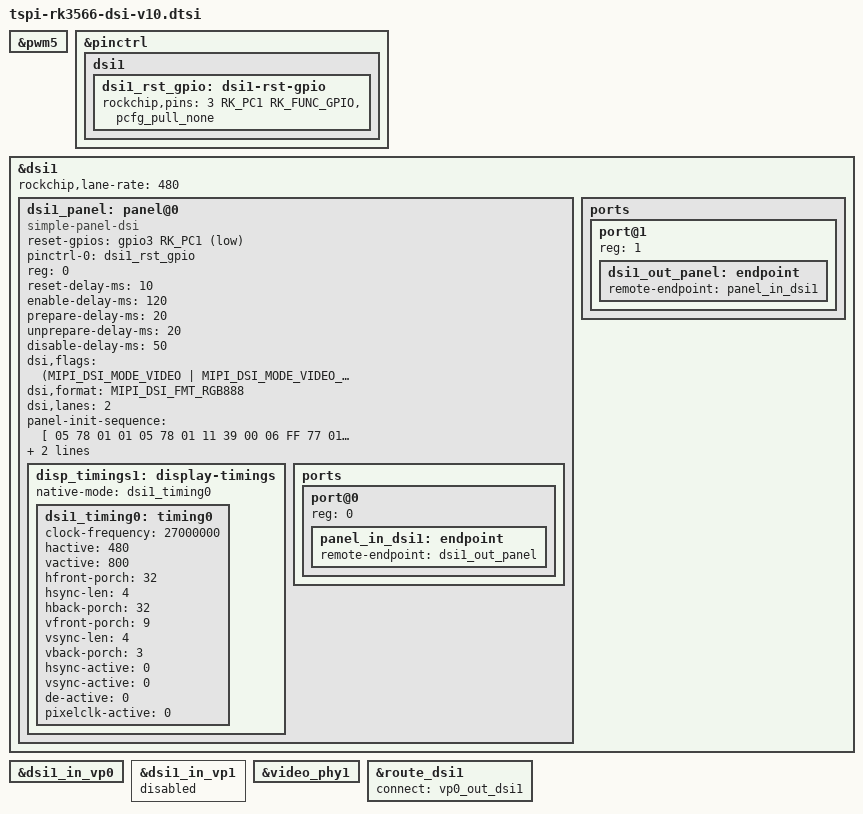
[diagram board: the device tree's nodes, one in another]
/*********************************************************************
 *           立创开发板不靠卖板赚钱，以培养中国工程师为己任  
 *         泰山派软硬件资料与相关扩展板软硬件资料官网全部开源
 *                      开发板官网：www.lckfb.com            
 *                     立创论坛：oshwhub.com/forum           
 *            关注B站：【立创开发板】，掌握我们的最新动态！  
 *********************************************************************
 * 文件名：tspi-rk3566-dsi-v10.dtsi
 * 描述：mipi 屏幕
 * 更新:
 * 时间          作者           联系           说明
 * 2023-09-13   吴才成    1378913492@qq.com   v1.0.0
 *********************************************************************/
/ {
	/*backlight: backlight {
		compatible = "pwm-backlight";
		pwms = <&pwm5 0 25000 0>;
		brightness-levels = <
			  0  20  20  21  21  22  22  23
			 23  24  24  25  25  26  26  27
			 27  28  28  29  29  30  30  31
			 31  32  32  33  33  34  34  35
			 35  36  36  37  37  38  38  39
			 40  41  42  43  44  45  46  47
			 48  49  50  51  52  53  54  55
			 56  57  58  59  60  61  62  63
			 64  65  66  67  68  69  70  71
			 72  73  74  75  76  77  78  79
			 80  81  82  83  84  85  86  87
			 88  89  90  91  92  93  94  95
			 96  97  98  99 100 101 102 103
			104 105 106 107 108 109 110 111
			112 113 114 115 116 117 118 119
			120 121 122 123 124 125 126 127
			128 129 130 131 132 133 134 135
			136 137 138 139 140 141 142 143
			144 145 146 147 148 149 150 151
			152 153 154 155 156 157 158 159
			160 161 162 163 164 165 166 167
			168 169 170 171 172 173 174 175
			176 177 178 179 180 181 182 183
			184 185 186 187 188 189 190 191
			192 193 194 195 196 197 198 199
			200 201 202 203 204 205 206 207
			208 209 210 211 212 213 214 215
			216 217 218 219 220 221 222 223
			224 225 226 227 228 229 230 231
			232 233 234 235 236 237 238 239
			240 241 242 243 244 245 246 247
			248 249 250 251 252 253 254 255
		>;
		default-brightness-level = <255>;
	};*/
};

&pwm5 {
	status = "okay";
};


&pinctrl {
	dsi1 {
		dsi1_rst_gpio: dsi1-rst-gpio {
			rockchip,pins = <3 RK_PC1 RK_FUNC_GPIO &pcfg_pull_none>;
		};
	};
};

/*
 * video_phy1 needs to be enabled
 * when dsi1 is enabled
 */
&dsi1 {
	status = "okay";
};

&dsi1_in_vp0 {
	status = "okay";
};

&dsi1_in_vp1 {
	status = "disabled";
};

&video_phy1 {
	status = "okay";
};

&route_dsi1 {
	status = "okay";//wucaicheng mipi okay
	connect = <&vp0_out_dsi1>;
};

//默认 8寸800x1280
&dsi1 {
	status = "okay";
	rockchip,lane-rate = <480>;
	dsi1_panel: panel@0 {
		status = "okay";
		compatible = "simple-panel-dsi";
		reset-gpios = <&gpio3 RK_PC1 GPIO_ACTIVE_LOW>;
		pinctrl-names = "default";
		pinctrl-0 = <&dsi1_rst_gpio>;
		reg = <0>;
		/*backlight = <&backlight>;*/
		reset-delay-ms = <10>;
		enable-delay-ms = <120>;
		prepare-delay-ms = <20>;
		unprepare-delay-ms = <20>;
		disable-delay-ms = <50>;
		dsi,flags = <(MIPI_DSI_MODE_VIDEO | MIPI_DSI_MODE_VIDEO_BURST |
			MIPI_DSI_MODE_LPM | MIPI_DSI_MODE_EOT_PACKET)>;
		dsi,format = <MIPI_DSI_FMT_RGB888>;
		dsi,lanes  = <2>;
		panel-init-sequence = [
			// init code
			05 78 01 01
			05 78 01 11
			39 00 06 FF 77 01 00 00 11
			15 00 02 D1 11
			15 00 02 55 B0 // 80 90 b0
			39 00 06 FF 77 01 00 00 10
			39 00 03 C0 63 00
			39 00 03 C1 09 02
			39 00 03 C2 37 08
			15 00 02 C7 00 // x-dir rotate 0:0x00,rotate 180:0x04
			15 00 02 CC 38
			39 00 11 B0 00 11 19 0C 10 06 07 0A 09 22 04 10 0E 28 30 1C
			39 00 11 B1 00 12 19 0D 10 04 06 07 08 23 04 12 11 28 30 1C
			39 00 06 FF 77 01 00 00 11 // enable  bk fun of  command 2  BK1
			15 00 02 B0 4D
			15 00 02 B1 60 // 0x56  0x4a  0x5b
			15 00 02 B2 07
			15 00 02 B3 80
			15 00 02 B5 47
			15 00 02 B7 8A
			15 00 02 B8 21
			15 00 02 C1 78
			15 00 02 C2 78
			15 64 02 D0 88
			39 00 04 E0 00 00 02
			39 00 0C E1 01 A0 03 A0 02 A0 04 A0 00 44 44
			39 00 0D E2 00 00 00 00 00 00 00 00 00 00 00 00
			39 00 05 E3 00 00 33 33
			39 00 03 E4 44 44
			39 00 11 E5 01 26 A0 A0 03 28 A0 A0 05 2A A0 A0 07 2C A0 A0
			39 00 05 E6 00 00 33 33
			39 00 03 E7 44 44
			39 00 11 E8 02 26 A0 A0 04 28 A0 A0 06 2A A0 A0 08 2C A0 A0
			39 00 08 EB 00 01 E4 E4 44 00 40
			39 00 11 ED FF F7 65 4F 0B A1 CF FF FF FC 1A B0 F4 56 7F FF
			39 00 06 FF 77 01 00 00 00
			15 00 02 36 00 //U&D  Y-DIR rotate 0:0x00,rotate 180:0x10
			15 00 02 3A 55
			05 78 01 11
			05 14 01 29
		];

		panel-exit-sequence = [
			05 00 01 28
			05 00 01 10
		];

		disp_timings1: display-timings {
			native-mode = <&dsi1_timing0>;
			dsi1_timing0: timing0 {
				clock-frequency = <27000000>;
				hactive = <480>;       //与 LCDTiming.LCDH 对应
				vactive = <800>;       //与 LCDTiming.LCDV 对应
				hfront-porch = <32>;   //与 LCDTiming.HFPD 对应
				hsync-len = <4>;       //与 LCDTiming.HSPW 对应
				hback-porch = <32>;    //与 LCDTiming.HBPD 对应
				vfront-porch = <9>;    //与 LCDTiming.VEPD 对应
				vsync-len = <4>;       //与 LCDTiming.VsPW 对应
				vback-porch = <3>;     //与 LCDTiming.VBPD 对应
				hsync-active = <0>;
				vsync-active = <0>;
				de-active = <0>;
				pixelclk-active = <0>;
			};
		};

		ports {
			#address-cells = <1>;
			#size-cells = <0>;

			port@0 {
				reg = <0>;
				panel_in_dsi1: endpoint {
					remote-endpoint = <&dsi1_out_panel>;
				};
			};
		};
	};

	ports {
		#address-cells = <1>;
		#size-cells = <0>;

		port@1 {
			reg = <1>;
			dsi1_out_panel: endpoint {
				remote-endpoint = <&panel_in_dsi1>;
			};
		};
	};

};

// &dsi1 {
// 	status = "okay";
// 	rockchip,lane-rate = <1000>;
// 	dsi1_panel: panel@0 {
// 		status = "okay";
// 		compatible = "simple-panel-dsi";
// 		reset-gpios = <&gpio3 RK_PC1 GPIO_ACTIVE_LOW>;
// 		pinctrl-names = "default";
// 		pinctrl-0 = <&dsi1_rst_gpio>;
// 		reg = <0>;
// 		backlight = <&backlight>;
// 		reset-delay-ms = <100>;
// 		enable-delay-ms = <120>;
// 		prepare-delay-ms = <20>;
// 		unprepare-delay-ms = <20>;
// 		disable-delay-ms = <100>;
// 		dsi,flags = <(MIPI_DSI_MODE_VIDEO | MIPI_DSI_MODE_VIDEO_BURST |
// 			MIPI_DSI_MODE_LPM | MIPI_DSI_MODE_EOT_PACKET)>;
// 		dsi,format = <MIPI_DSI_FMT_RGB888>;
// 		dsi,lanes  = <4>;
// 		panel-init-sequence = [
// 			15 00 02 B0 01
// 			15 00 02 C3 4F
// 			15 00 02 C4 40
// 			15 00 02 C5 40
// 			15 00 02 C6 40
// 			15 00 02 C7 40
// 			15 00 02 C8 4D
// 			15 00 02 C9 52
// 			15 00 02 CA 51
// 			15 00 02 CD 5D
// 			15 00 02 CE 5B
// 			15 00 02 CF 4B
// 			15 00 02 D0 49
// 			15 00 02 D1 47
// 			15 00 02 D2 45
// 			15 00 02 D3 41
// 			15 00 02 D7 50
// 			15 00 02 D8 40
// 			15 00 02 D9 40
// 			15 00 02 DA 40
// 			15 00 02 DB 40
// 			15 00 02 DC 4E
// 			15 00 02 DD 52
// 			15 00 02 DE 51
// 			15 00 02 E1 5E
// 			15 00 02 E2 5C
// 			15 00 02 E3 4C
// 			15 00 02 E4 4A
// 			15 00 02 E5 48
// 			15 00 02 E6 46
// 			15 00 02 E7 42
// 			15 00 02 B0 03
// 			15 00 02 BE 03
// 			15 00 02 CC 44
// 			15 00 02 C8 07
// 			15 00 02 C9 05
// 			15 00 02 CA 42
// 			15 00 02 CD 3E
// 			15 00 02 CF 60
// 			15 00 02 D2 04
// 			15 00 02 D3 04
// 			15 00 02 D4 01
// 			15 00 02 D5 00
// 			15 00 02 D6 03
// 			15 00 02 D7 04
// 			15 00 02 D9 01
// 			15 00 02 DB 01
// 			15 00 02 E4 F0
// 			15 00 02 E5 0A
// 			15 00 02 B0 00
// 			15 00 02 B1 08
// 			15 00 02 BD 54
// 			15 00 02 C2 06
// 			15 00 02 C4 0B
// 			15 00 02 B0 02
// 			15 00 02 C0 00
// 			15 00 02 C1 0A
// 			15 00 02 C2 20
// 			15 00 02 C3 24
// 			15 00 02 C4 23
// 			15 00 02 C5 29
// 			15 00 02 C6 23
// 			15 00 02 C7 1C
// 			15 00 02 C8 19
// 			15 00 02 C9 17
// 			15 00 02 CA 17
// 			15 00 02 CB 18
// 			15 00 02 CC 1A
// 			15 00 02 CD 1E
// 			15 00 02 CE 20
// 			15 00 02 CF 23
// 			15 00 02 D0 07
// 			15 00 02 D1 00
// 			15 00 02 D2 00
// 			15 00 02 D3 0A
// 			15 00 02 D4 13
// 			15 00 02 D5 1C
// 			15 00 02 D6 1A
// 			15 00 02 D7 13
// 			15 00 02 D8 17
// 			15 00 02 D9 1C
// 			15 00 02 DA 19
// 			15 00 02 DB 17
// 			15 00 02 DC 17
// 			15 00 02 DD 18
// 			15 00 02 DE 1A
// 			15 00 02 DF 1E
// 			15 00 02 E0 20
// 			15 00 02 E1 23
// 			15 00 02 E2 07
// 			05 78 01 11
// 			05 14 01 29
// 		];

// 		panel-exit-sequence = [
// 			05 00 01 28
// 			05 00 01 10
// 		];

// 		disp_timings1: display-timings {
// 			native-mode = <&dsi1_timing0>;
// 			dsi1_timing0: timing0 {
// 				clock-frequency = <156000000>;
// 				hactive = <1200 >;
// 				vactive = <1920>;
// 				hfront-porch = <42>;
// 				hsync-len = <10>;
// 				hback-porch = <32>;
// 				vfront-porch = <35>;
// 				vsync-len = <4>;
// 				vback-porch = <30>;
// 				hsync-active = <0>;
// 				vsync-active = <0>;
// 				de-active = <0>;
// 				pixelclk-active = <0>;
// 			};
// 		};

// 		ports {
// 			#address-cells = <1>;
// 			#size-cells = <0>;

// 			port@0 {
// 				reg = <0>;
// 				panel_in_dsi1: endpoint {
// 					remote-endpoint = <&dsi1_out_panel>;
// 				};
// 			};
// 		};
// 	};

// 	ports {
// 		#address-cells = <1>;
// 		#size-cells = <0>;

// 		port@1 {
// 			reg = <1>;
// 			dsi1_out_panel: endpoint {
// 				remote-endpoint = <&panel_in_dsi1>;
// 			};
// 		};
// 	};

// };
